# DSS_EDP0_V2A_CORE_VP_REGS_APB register map
Vendor: Texas Instruments
Registers are 32-bit, access per field, reset 0x0 unless marked. A register's access mark holds for its fields unless they carry their own. Offsets are as the file gives them; [hi:lo] are bit positions; {n}, {i} and the like mark numbered series.

## DSS_EDP0_V2A_CORE_VP_REGS_APB (part 3 of 3)
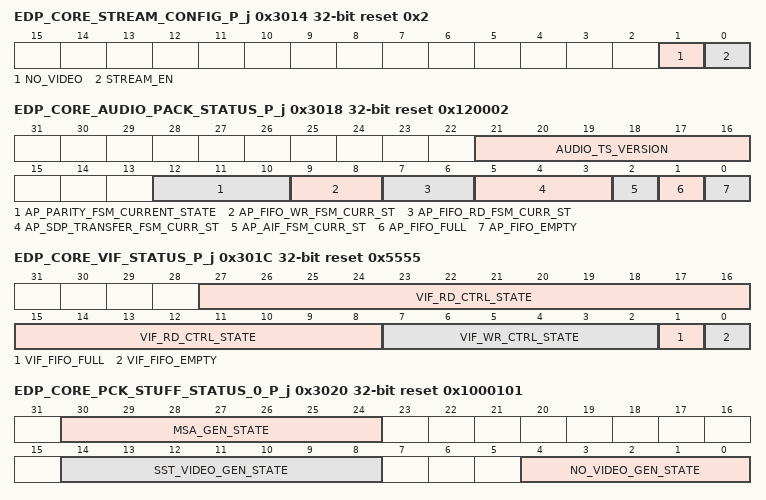
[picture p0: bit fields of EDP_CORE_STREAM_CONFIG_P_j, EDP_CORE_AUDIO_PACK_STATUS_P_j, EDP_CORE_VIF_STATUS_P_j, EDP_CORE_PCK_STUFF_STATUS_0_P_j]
0x3014 EDP_CORE_STREAM_CONFIG_P_j reset 0x2 — Stream configuration register. Used only in MST mode. Offset = 3014h + (j * 80h); where j = 0h to 3h
  [1] NO_VIDEO rw — Stream no video mode.
  [0] STREAM_EN rw — Stream enable.
0x3018 EDP_CORE_AUDIO_PACK_STATUS_P_j reset 0x120002 — Status signals for the audio pack. Offset = 3018h + (j * 80h); where j = 0h to 3h
  [21:16] AUDIO_TS_VERSION rw — Audio timestamp version.
  [12:10] AP_PARITY_FSM_CURRENT_STATE ro — Audio pack parity calc fsm state.
  [9:8] AP_FIFO_WR_FSM_CURR_ST ro — Audio pack FIFO write fsm state.
  [7:6] AP_FIFO_RD_FSM_CURR_ST ro — Audio pack FIFO read fsm state.
  [5:3] AP_SDP_TRANSFER_FSM_CURR_ST ro — Audio pack sdp transfer fsm state.
  [2] AP_AIF_FSM_CURR_ST ro — Audio pack aif fsm state.
  [1] AP_FIFO_FULL ro — Audio Pack Sync FIFO full flag, active high.
  [0] AP_FIFO_EMPTY ro — Audio Pack Sync FIFO empty flag, active high.
0x301C EDP_CORE_VIF_STATUS_P_j ro reset 0x5555 — Status signals for the VIF module. Used only for debug purposes. Offset = 301Ch + (j * 80h); where j = 0h to 3h
  [27:8] VIF_RD_CTRL_STATE — VIF rd fsm current state.
  [7:2] VIF_WR_CTRL_STATE — VIF wr fsm current state.
  [1] VIF_FIFO_FULL — VIF ASync FIFO full flag, active high.
  [0] VIF_FIFO_EMPTY — VIF ASync FIFO empty flag, active high.
0x3020 EDP_CORE_PCK_STUFF_STATUS_0_P_j ro reset 0x1000101 — Status of the the video stuff module (0). Used only for debug purposes. Offset = 3020h + (j * 80h); where j = 0h to 3h
  [30:24] MSA_GEN_STATE — Secondary Data generator FSM status.
  [14:8] SST_VIDEO_GEN_STATE — SST video generator FSM status.
  [4:0] NO_VIDEO_GEN_STATE — No video generator FSM status.
0x3024 EDP_CORE_PCK_STUFF_STATUS_1_P_j ro reset 0x1 — Status of the the video stuff module (1). Used only for debug purposes. Offset = 3024h + (j * 80h); where j = 0h to 3h
  [5:0] SST_SS_GEN_STATE — MSA generator FSM status.
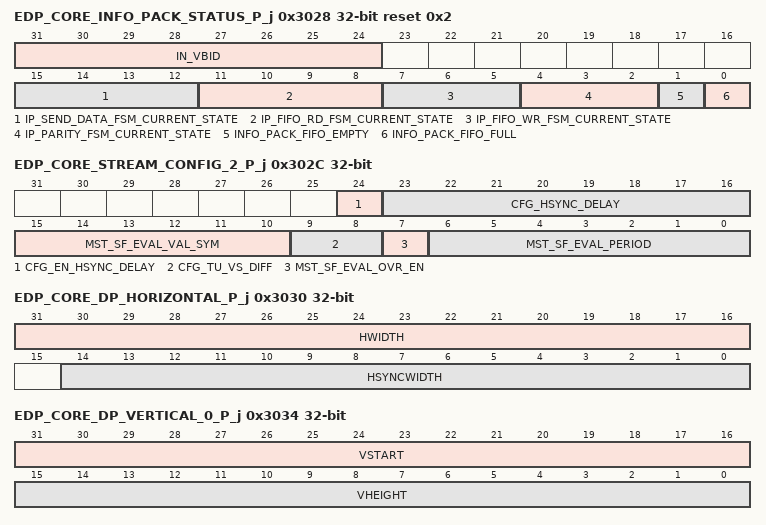
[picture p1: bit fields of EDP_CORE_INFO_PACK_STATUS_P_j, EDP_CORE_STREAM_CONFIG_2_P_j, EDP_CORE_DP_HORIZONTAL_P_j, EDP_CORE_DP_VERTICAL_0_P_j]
0x3028 EDP_CORE_INFO_PACK_STATUS_P_j ro reset 0x2 — Status signals for the info pack module, as well as final VB-ID value. Used only for debug purposes. Offset = 3028h + (j * 80h); where j = 0h to 3h
  [31:24] IN_VBID — Value of the sent VB-ID [vb_id_final].
  [15:12] IP_SEND_DATA_FSM_CURRENT_STATE — State of the send_data FSM.
  [11:8] IP_FIFO_RD_FSM_CURRENT_STATE — State of the fifo_rd FSM.
  [7:5] IP_FIFO_WR_FSM_CURRENT_STATE — State of the fifo_wr FSM.
  [4:2] IP_PARITY_FSM_CURRENT_STATE — State of the parity FSM.
  [1] INFO_PACK_FIFO_EMPTY — Info_pack fifo empty flag, active high.
  [0] INFO_PACK_FIFO_FULL — Info_pack fifo full flag, active high.
0x302C EDP_CORE_STREAM_CONFIG_2_P_j — Additional video stream configuration. Used for debug purposes or for non-standard video formats. Offset = 302Ch + (j * 80h); where j = 0h to 3h
  [24] CFG_EN_HSYNC_DELAY rw — Unused.
  [23:16] CFG_HSYNC_DELAY rw — Unused.
  [15:10] MST_SF_EVAL_VAL_SYM rw — Number of valid symbols to output during stream fill evaluation period.
  [9:8] CFG_TU_VS_DIFF rw — Unused.
  [7] MST_SF_EVAL_OVR_EN rw — Enable override of mst_sf_eval_period, mst_sf_eval_val_sym and cfg_tu_vs_diff when in MST mode.
  [6:0] MST_SF_EVAL_PERIOD rw — Stream fill evaluation period when in MST mode and mst_sf_eval_ovr_en bit is set.
0x3030 EDP_CORE_DP_HORIZONTAL_P_j — Video Horizontal parameters. This register must be programmed prior enabling video and must not be changed while video is being transmitted.In case of compressed stream transmission (DSC) and split panel mode values in this register must be divided by 2 since VIF interface operates at pixel clock divided by 2. This will ensure the same timing compared to uncompressed stream and. Offset = 3030h + (j * 80h); where j = 0h to 3h
  [31:16] HWIDTH rw — Horizontal Active Video Width.
  [14:0] HSYNCWIDTH rw — Horizontal Sync Width.
0x3034 EDP_CORE_DP_VERTICAL_0_P_j rw — Video Vertical parameters. This register must be programmed prior enabling video and must not be changed while video is being transmitted. Offset = 3034h + (j * 80h); where j = 0h to 3h
  [31:16] VSTART — Vertical Active Start [VSTART].
  [15:0] VHEIGHT — Vertical Active High [VACTIVE].
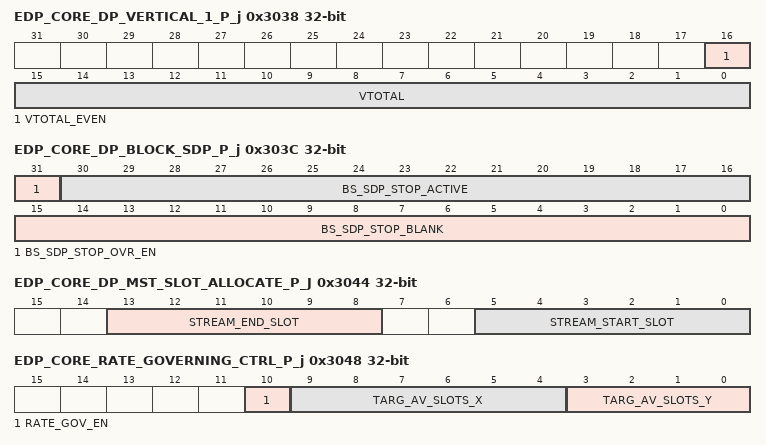
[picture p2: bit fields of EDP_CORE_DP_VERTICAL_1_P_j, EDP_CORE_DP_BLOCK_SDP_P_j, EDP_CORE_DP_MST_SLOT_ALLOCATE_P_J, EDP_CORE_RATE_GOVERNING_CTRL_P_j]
0x3038 EDP_CORE_DP_VERTICAL_1_P_j — Video Vertical parameters. This register must be programmed prior enabling video and must not be changed while video is being transmitted. Offset = 3038h + (j * 80h); where j = 0h to 3h
  [16] VTOTAL_EVEN rw — Indicate Vtotal is an even number as described in MISC1[0] in DisplayPort specification.
  [15:0] VTOTAL rw — Vertical Total Heigh [HTOTAL].
0x303C EDP_CORE_DP_BLOCK_SDP_P_j rw — SDP scheduling control register. Allows for tuning when SDP can be sent during blanking periods. This register must be programmed prior enabling video and must not be changed while video is being transmitted. Offset = 303Ch + (j * 80h); where j = 0h to 3h
  [31] BS_SDP_STOP_OVR_EN — Enable override settings.
  [30:16] BS_SDP_STOP_ACTIVE — Block SDP scheduling after specified cycles after BS during horizontal blank lines.
  [15:0] BS_SDP_STOP_BLANK — Block SDP scheduling after specified cycles after BS during vertical blank lines.
0x3044 EDP_CORE_DP_MST_SLOT_ALLOCATE_P_J — Stream slots allocation in MST mode. This register defines slots in the MTP assigned to a given stream. All slots between start and and are assigned to the stream. Assignement of noncontiguous slots to a single stream is not supported. Offset = 3044h + (j * 80h); where j = 0h to 3h
  [13:8] STREAM_END_SLOT rw, [5:0] STREAM_START_SLOT rw
0x3048 EDP_CORE_RATE_GOVERNING_CTRL_P_j — Control rate governing for stream in MST mode. Offset = 3048h + (j * 80h); where j = 0h to 3h
  [10] RATE_GOV_EN rw — Enable rate governing.
  [9:4] TARG_AV_SLOTS_X rw — Target average number of slots per MTP configuration
  [3:0] TARG_AV_SLOTS_Y rw — Target average number of slots per MTP configuration.
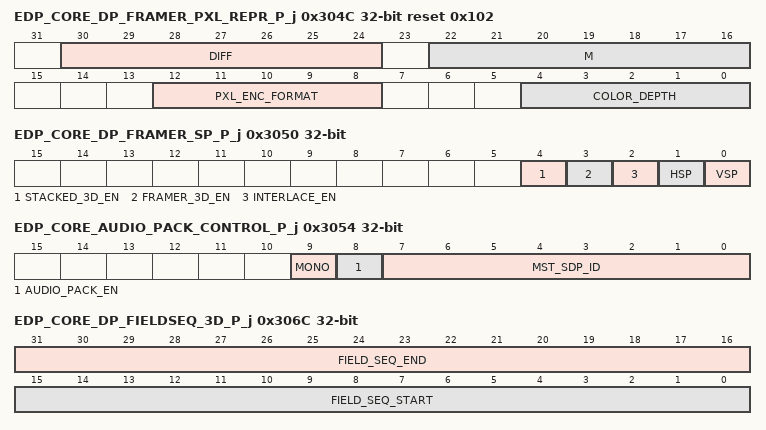
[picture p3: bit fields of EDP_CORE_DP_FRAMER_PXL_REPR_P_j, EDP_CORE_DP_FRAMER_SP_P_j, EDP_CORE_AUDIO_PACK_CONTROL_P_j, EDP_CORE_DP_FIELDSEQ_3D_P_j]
0x304C EDP_CORE_DP_FRAMER_PXL_REPR_P_j reset 0x102 — Video pixel format configuration. This register must be programmed prior enabling video and must not be changed while video is being transmitted. Offset = 304Ch + (j * 80h); where j = 0h to 3h
  [30:24] DIFF rw — Difference between Denominator and Numerator of the ratio that describes valid symbols distribution.
  [22:16] M rw — Numerator of the ratio that describes valid symbols distribution.
  [12:8] PXL_ENC_FORMAT rw — Pixel encoding format:
  [4:0] COLOR_DEPTH rw
0x3050 EDP_CORE_DP_FRAMER_SP_P_j — Synchronization signals polarity and 3D control. This register must be programmed prior enabling video and must not be changed while video is being transmitted. Offset = 3050h + (j * 80h); where j = 0h to 3h
  [4] STACKED_3D_EN rw — Unused.
  [3] FRAMER_3D_EN rw — 3D video enable, active high.
  [2] INTERLACE_EN rw — Interlaced video enable.
  [1] HSP rw — Video interface HSYNC polarity:
  [0] VSP rw — Video interface VSYNC polarity:
0x3054 EDP_CORE_AUDIO_PACK_CONTROL_P_j — Audio packet configuration. Offset = 3054h + (j * 80h); where j = 0h to 3h
  [9] MONO rw — In case of
  [8] AUDIO_PACK_EN rw — Enables the Audio_Pack module, active high
  [7:0] MST_SDP_ID rw — Secondary-Data Packet ID.
0x3064 EDP_CORE_LINE_THRESH_P_j reset 0x20 — Video FIFO latency threshold Offset = 3064h + (j * 80h); where j = 0h to 3h
  [5:0] CFG_ACTIVE_LINE_TRESH rw — Video Fifo Latency threshold.
0x3068 EDP_CORE_DP_VB_ID_P_J reset 0x9 — Vertical blanking ID Offset = 3068h + (j * 80h); where j = 0h to 3h
  [7:0] VB_ID rw — VB-ID as described in the DisplayPort specification.
0x306C EDP_CORE_DP_FIELDSEQ_3D_P_j rw — Supporting configuration to switch from top/bottom on the input to field sequential on the output Offset = 306Ch + (j * 80h); where j = 0h to 3h
  [31:16] FIELD_SEQ_END — Number of line in the frame where the Vblank part in the field sequential format ends
  [15:0] FIELD_SEQ_START — Number of line in the frame where the Vblank part in the field sequential format starts
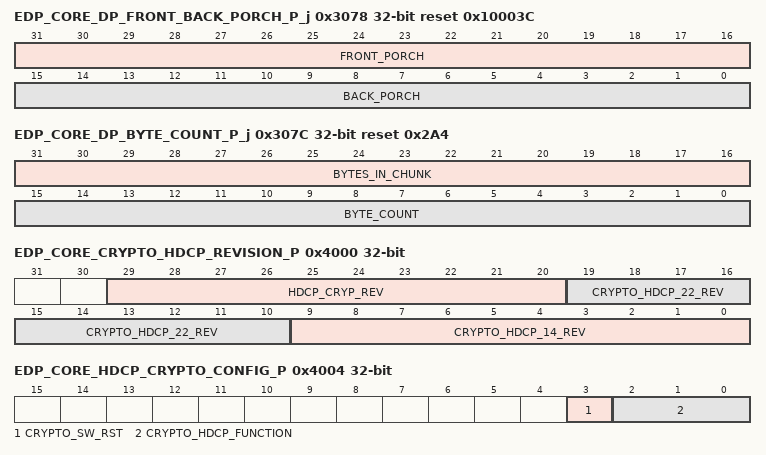
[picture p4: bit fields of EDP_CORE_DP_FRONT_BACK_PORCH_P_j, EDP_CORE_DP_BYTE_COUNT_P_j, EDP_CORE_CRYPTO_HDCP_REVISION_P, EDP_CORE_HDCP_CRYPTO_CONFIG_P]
0x3078 EDP_CORE_DP_FRONT_BACK_PORCH_P_j rw reset 0x10003C — Front and Back Porch configuration register.In case of compressed stream transmission (DSC) and split panel mode values in this register must be divided by 2 since VIF interface operates at pixel clock divided by 2. This will ensure the same timing compared to uncompressed stream and. Offset = 3078h + (j * 80h); where j = 0h to 3h
  [31:16] FRONT_PORCH — Value of the front porch
  [15:0] BACK_PORCH — Value of the back porch
0x307C EDP_CORE_DP_BYTE_COUNT_P_j rw reset 0x2A4 — Number of bytes per lane/chunk parameters Offset = 307Ch + (j * 80h); where j = 0h to 3h
  [31:16] BYTES_IN_CHUNK — Number of bytes in chunk per lane, including additional EOC symbol.
  [15:0] BYTE_COUNT — Total number of bytes in a line in case of non-DSC video.
0x4000 EDP_CORE_CRYPTO_HDCP_REVISION_P ro — Contains the revision of the internal HDCP 1.4 and 2.2 module.
  [29:20] HDCP_CRYP_REV — Revision of the HDCP Crypto block.
  [19:10] CRYPTO_HDCP_22_REV — Revision of the HDCP Crypto 2.2 block.
  [9:0] CRYPTO_HDCP_14_REV — Revision of the HDCP Crypto 1.4 block.
0x4004 EDP_CORE_HDCP_CRYPTO_CONFIG_P — Contains global configuration information for the HDCP Crypto module.
  [3] CRYPTO_SW_RST rw — Software reset for the Crypto module.
  [2:0] CRYPTO_HDCP_FUNCTION rw — Enables a version of the Crypto function:
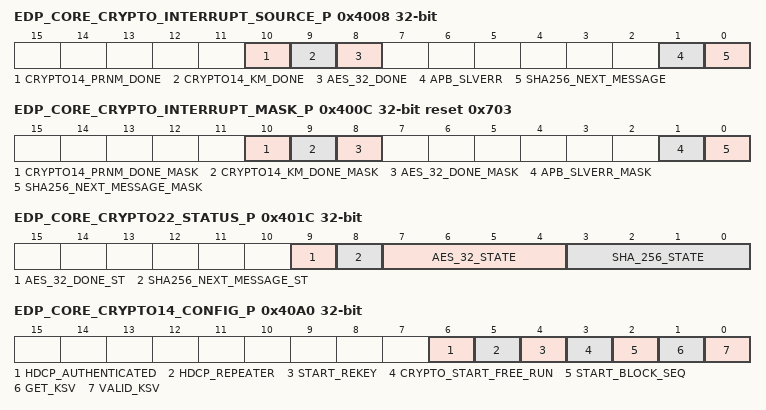
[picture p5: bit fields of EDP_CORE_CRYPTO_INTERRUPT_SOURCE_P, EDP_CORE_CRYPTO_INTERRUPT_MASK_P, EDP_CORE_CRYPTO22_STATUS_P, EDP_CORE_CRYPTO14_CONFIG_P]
0x4008 EDP_CORE_CRYPTO_INTERRUPT_SOURCE_P ro — Contains the status of the HDCP interrupt sources. These interrupts are used by firmware and not directly visible to the Host processor.
  [10] CRYPTO14_PRNM_DONE — LFSR and block output finished calculation.
  [9] CRYPTO14_KM_DONE — Done reading/calculating Km.
  [8] AES_32_DONE — Asserted when the rising edge of the AES-32 done output is detected.
  [1] APB_SLVERR — APB slave error.
  [0] SHA256_NEXT_MESSAGE — Asserted when the rising edge of the SHA256 done output is detected.
0x400C EDP_CORE_CRYPTO_INTERRUPT_MASK_P reset 0x703 — Contains the mask vector of the HDCP interrupt sources.
  [10] CRYPTO14_PRNM_DONE_MASK rw — Set to 1 to mask the crypto14_prnm_done interrupt.
  [9] CRYPTO14_KM_DONE_MASK rw — Set to 1 to mask the crypto14_km_done interrupt.
  [8] AES_32_DONE_MASK rw — Set to 1 to mask the AES32_done interrupt.
  [1] APB_SLVERR_MASK rw — Set to 1 for the apb_slverr interrupt.
  [0] SHA256_NEXT_MESSAGE_MASK rw — Set to 1 to mask the SHA256_done interrupt.
0x4018 EDP_CORE_CRYPTO22_CONFIG_P — Contains global configuration information for the HDCP 2.2 Crypto module
  [0] SHA_256_START rw — Set to 1 for Sha-256 start.
0x401C EDP_CORE_CRYPTO22_STATUS_P ro — Crypto 2.2 global status register.
  [9] AES_32_DONE_ST — Asserted when the rising edge of the AES-32 done output is detected.
  [8] SHA256_NEXT_MESSAGE_ST — Asserted when the SHA-256 module is ready to receive the next message.
  [7:4] AES_32_STATE — AES-32 current state.
  [3:0] SHA_256_STATE — SHA-256 current state.
0x403C EDP_CORE_SHA_256_DATA_IN_P rw — Holds 32-bit input data word of the SHA-256 module.
  [31:0] SHA_256_DATA_IN — Holds the 32-bit input data word of the SHA-256 module.
0x4050 EDP_CORE_SHA_256_DATA_OUT_0_P ro — Result of operation SHA-256 - 1' dw
  [31:0] SHA_256_DATA_OUT_0 — Holds the least significant 32-bits word of the 256-bits output data word of the SHA-256 module.
0x4054 EDP_CORE_SHA_256_DATA_OUT_1_P ro — Result of operation SHA-256 - 2' dw
  [31:0] SHA_256_DATA_OUT_1 — Holds the next significant 32-bits word of the 256-bits output data word of the SHA-256 module.
0x4058 EDP_CORE_SHA_256_DATA_OUT_2_P ro — Result of operation SHA-256 - 3' dw
  [31:0] SHA_256_DATA_OUT_2 — Holds the next significant 32-bits word of the 256-bits output data word of the SHA-256 module
{0x4050+4i} EDP_CORE_SHA_256_DATA_OUT_{i}_P ro (i=3..6) — Result of operation SHA-256 - {i+1}' dw
  [31:0] SHA_256_DATA_OUT_{i} — Holds the next significant 32-bits word of the 256-bits output data word of the SHA-256 module.
0x406C EDP_CORE_SHA_256_DATA_OUT_7_P ro — Result of operation SHA-256 - 8' dw
  [31:0] SHA_256_DATA_OUT_7 — Holds the most significant 32-bits word of the 256-bits output data word of the SHA-256 module.
0x4070 EDP_CORE_AES_32_KEY_0_P rw — Input key word of the AES-32 module - 1' dw
  [31:0] AES_32_KEY_0 — Holds the least significant 32-bits word of the 128-bits input key word of the AES-32 module.
0x4074 EDP_CORE_AES_32_KEY_1_P rw — Input key word of the AES-32 module - 2' dw
  [31:0] AES_32_KEY_1 — Holds the next significant 32-bits word of the 128-bits input key word of the AES-32 module.
0x4078 EDP_CORE_AES_32_KEY_2_P rw — Input key word of the AES-32 module - 3' dw
  [31:0] AES_32_KEY_2 — Holds the next significant 32-bits word of the 128-bits input key word of the AES-32 module.
0x407C EDP_CORE_AES_32_KEY_3_P rw — Input key word of the AES-32 module - 4' dw
  [31:0] AES_32_KEY_3 — Holds the most significant 32-bits word of the 128-bits input key word of the AES-32 module.
0x4080 EDP_CORE_AES_32_DATA_IN_P rw — Input data word to the AES-32 module
  [31:0] AES_32_DATA_IN — Holds the input data word to the AES-32 module.
0x4084 EDP_CORE_AES_32_DATA_OUT_0_P ro — AES-32 module - 128-bits output data word - 1' dw
  [31:0] AES_32_DATA_OUT_0 — Holds the least significant 32-bits word of the 128-bits output data word of the AES-32 module.
0x4088 EDP_CORE_AES_32_DATA_OUT_1_P ro — AES-32 module - 128-bits output data word - 2' dw
  [31:0] AES_32_DATA_OUT_1 — Holds the next significant 32-bits word of the 128-bits output data word of the AES-32 module.
0x408C EDP_CORE_AES_32_DATA_OUT_2_P ro — AES-32 module - 128-bits output data word - 3' dw
  [31:0] AES_32_DATA_OUT_2 — Holds the next significant 32-bits word of the 128-bits output data word of the AES-32 module.
0x4090 EDP_CORE_AES_32_DATA_OUT_3_P ro — AES-32 module - 128-bits output data word - 4' dw
  [31:0] AES_32_DATA_OUT_3 — Holds the most significant 32-bits word of the 128-bits output data word of the AES-32 module.
0x40A0 EDP_CORE_CRYPTO14_CONFIG_P — Contains global configuration information for the HDCP 1.4 Crypto module
  [6] HDCP_AUTHENTICATED rw — Authenticated finished.
  [5] HDCP_REPEATER rw — Repeater bit :
  [4] START_REKEY rw — Crypto 1.4 command to start hdcpRekeyCipher
  [3] CRYPTO_START_FREE_RUN rw — Crypto 1.4 command to start free running enable for operation hdcpRngCipher
  [2] START_BLOCK_SEQ rw — Crypto 1.4 command to start LFSR calculation
  [1] GET_KSV rw — Read it's own KSV enable bit.'0' reading not allowed'1' start reading.
  [0] VALID_KSV rw — Enable for Km calculation.
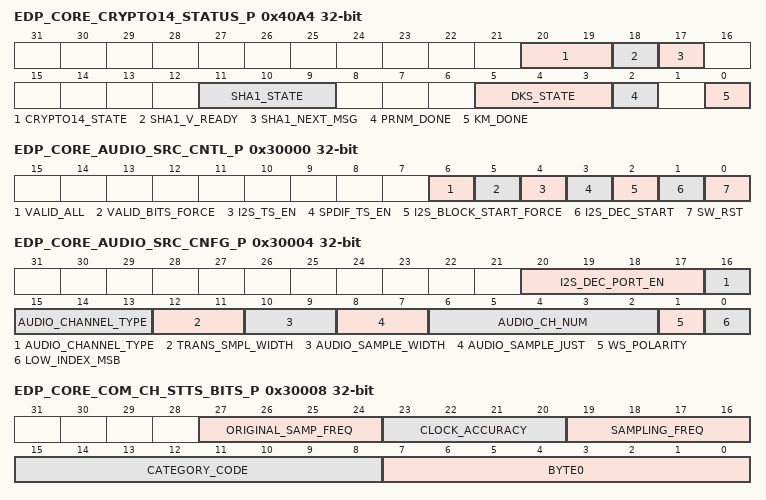
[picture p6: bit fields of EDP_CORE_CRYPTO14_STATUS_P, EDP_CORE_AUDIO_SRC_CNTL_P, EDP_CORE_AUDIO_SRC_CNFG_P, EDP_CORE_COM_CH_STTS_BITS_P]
0x40A4 EDP_CORE_CRYPTO14_STATUS_P ro — Contains global status information for the HDCP 1.4 Crypto module
  [20:19] CRYPTO14_STATE — Crypto operation SM state: Possible values:
  [18] SHA1_V_READY — Indication that V value from SHA-1 CRYPTO14_SHA1_V_VALUE_4 is ready.
  [17] SHA1_NEXT_MSG — Request for the next message block.
  [11:9] SHA1_STATE — Current state for Crypto 1.4 SHA-1 FSM.
  [5:3] DKS_STATE — Crypto 1.4 DKS current state.
  [2] PRNM_DONE — LFSR and block output finished calculation.
  [0] KM_DONE — Done reading/calculating Km.
0x40A8 EDP_CORE_CRYPTO14_PRNM_OUT_P ro — Contains 24-bit pseudo random data
  [23:0] PRNM_OUT
0x40AC EDP_CORE_CRYPTO14_KM_0_P ro — Contains the first word of the Km value
  [31:0] CRYPTO14_KM_0 — Holds the first word of the Km value.
0x40B0 EDP_CORE_CRYPTO14_KM_1_P ro — Contains the most significant 3 bytes of the Km value
  [23:0] CRYPTO14_KM_1 — Holds the most significant 3 bytes of the Km value.
0x40B4 EDP_CORE_CRYPTO14_AN_0_P rw — First word of An value generated by hdcpRngCipher operation.
  [31:0] CRYPTO14_AN_0 — Holds the first 4 bytes of the An value.
0x40B8 EDP_CORE_CRYPTO14_AN_1_P rw — Second word of An value generated by hdcpRngCipher operation
  [31:0] CRYPTO14_AN_1 — Holds the most significant 4 bytes of the An value.
0x40BC EDP_CORE_CRYPTO14_YOUR_KSV_0_P rw — First 32 bits of the KSV from the other HDCP device
  [31:0] CRYPTO14_YOUR_KSV_0 — Holds the first 32 bits of the KSV from the other HDCP device.
0x40C0 EDP_CORE_CRYPTO14_YOUR_KSV_1_P — Last byte of the KSV from other HDCP device
  [7:0] CRYPTO14_YOUR_KSV_1 rw — Holds the last byte of the KSV from other HDCP device
0x40C4 EDP_CORE_CRYPTO14_MI_0_P ro — Mi value - 1' dw
  [31:0] CRYPTO14_MI_0 — Mi value first 32 bits
0x40C8 EDP_CORE_CRYPTO14_MI_1_P ro — Mi value - 2' dw
  [31:0] CRYPTO14_MI_1 — Mi value second 32 bits
0x40CC EDP_CORE_CRYPTO14_TI_0_P ro — Ti value
  [15:0] CRYPTO14_TI_0
0x40D0 EDP_CORE_CRYPTO14_KI_0_P ro — First 32 bits of the Ki frame key from this HDCP device
  [31:0] CRYPTO14_KI_0 — Holds the first 32 bits of the Ki frame key from this HDCP device.
0x40D4 EDP_CORE_CRYPTO14_KI_1_P ro — Last 3 bytes of the Ki frame key from this HDCP device.
  [23:0] CRYPTO14_KI_1 — Holds the last 3 bytes of the Ki frame key from this HDCP device.
0x40D8 EDP_CORE_CRYPTO14_BLOCKS_NUM_P rw — This register defines number of iterations for SHA-1 calculations
  [31:0] BLOCKS_NUM — Number of iterations for SHA-1 calculation.
0x40DC EDP_CORE_CRYPTO14_KEY_MEM_DATA_0_P rw — Key memory control register. Writing data to this register transfers data to the key RAM. This is input for DKS block. First 32 bits
  [31:0] KEY_MEM_DATA_0 — Output data from keys RAM.
0x40E0 EDP_CORE_CRYPTO14_KEY_MEM_DATA_1_P — Key memory control register. Writing data to this register transfers data to the key RAM. When data is written to this register, pulse key_mem_vld shall be also generated to the core_clk clock domain, as indication of new key_mem_data. This is input for DKS block. Last 3 bytes
  [23:0] KEY_MEM_DATA_1 rw — Output data from keys RAM.
0x40E4 EDP_CORE_CRYPTO14_SHA1_MSG_DATA_P rw — SHA1 message control register. 32-bit word for SHA-1 message. Input for SHA-1 block. Writing data to this register transfers data to the SHA-1 block. Write to this register shall be repeated 16 times.
  [31:0] SHA1_MSG_DATA — 32-bit word for SHA-1 message.
0x40E8 EDP_CORE_CRYPTO14_SHA1_V_VALUE_0_P ro reset 0x67452301 — SHA1 message status register. First 32-bit word for SHA-1 calculation. Output from SHA-1 block
  [31:0] V_VALUE_0 — First 32-bit word for SHA-1 calculation value.
0x40EC EDP_CORE_CRYPTO14_SHA1_V_VALUE_1_P ro reset 0xEFCDAB89 — SHA1 message status register. Second 32-bit word for SHA-1 calculation. Output from SHA-1 block
  [31:0] V_VALUE_1 — Second 32-bit word for SHA-1 calculation value.
0x40F0 EDP_CORE_CRYPTO14_SHA1_V_VALUE_2_P ro reset 0x98BADCFE — SHA1 message status register. Third 32-bit word for SHA-1 calculation. Output from SHA-1 block
  [31:0] V_VALUE_2 — Third 32-bit word for SHA-1 calculation value.
0x40F4 EDP_CORE_CRYPTO14_SHA1_V_VALUE_3_P ro reset 0x10325476 — SHA1 message status register. Third 32-bit word for SHA-1 calculation. Output from SHA-1 block
  [31:0] V_VALUE_3 — 4th 32-bit word for SHA-1 calculation value.
0x40F8 EDP_CORE_CRYPTO14_SHA1_V_VALUE_4_P ro reset 0xC3D2E1F0 — SHA1 message status register. 5th 32-bit word for SHA-1 calculation. Output from SHA-1 block
  [31:0] V_VALUE_4 — 5th 32-bit word for SHA-1 calculation value.
0x10000 EDP_CORE_IRAM_REG_P_y rw — Xtensa Instruction RAM address space. Accessed only during boot mode to load firmware. Offset = 00010000h + (y * 4h); where y = 0h to 3FFFh
  [31:0] IRAM_DATA
0x20000 EDP_CORE_DRAM_REG_P_y rw — Xtensa Data RAM address space. Accessed only during boot mode to load firmware. Offset = 00020000h + (y * 4h); where y = 0h to 3FFFh
  [31:0] DRAM_DATA
0x30000 EDP_CORE_AUDIO_SRC_CNTL_P — Audio source control
  [6] VALID_ALL rw — valid bit for all samples
  [5] VALID_BITS_FORCE rw — Force valid bits of the channels
  [4] I2S_TS_EN rw — Enable I2S Time Stamp when decoders are disabled
  [3] SPDIF_TS_EN rw — Enable SPDIF Time Stamp when decoders are disabled
  [2] I2S_BLOCK_START_FORCE rw — Force a Block Start in the audio stream
  [1] I2S_DEC_START rw — When high Source Decoder starts.
  [0] SW_RST rw — Software reset.
0x30004 EDP_CORE_AUDIO_SRC_CNFG_P — Audio source configuration
  [20:17] I2S_DEC_PORT_EN rw — Enables the I2S Decoder ports.
  [16:13] AUDIO_CHANNEL_TYPE rw — Set the transmission type.
  [12:11] TRANS_SMPL_WIDTH rw — Decoder Word Select width:
  [10:9] AUDIO_SAMPLE_WIDTH rw — Decoder sample width:
  [8:7] AUDIO_SAMPLE_JUST rw — Data justification setting:
  [6:2] AUDIO_CH_NUM rw — Number of channels to decode
  [1] WS_POLARITY rw — Word Select Polarity.
  [0] LOW_INDEX_MSB rw — When low MSB is transmitted first.
0x30008 EDP_CORE_COM_CH_STTS_BITS_P — Common channels configuration
  [27:24] ORIGINAL_SAMP_FREQ rw — Original Sampling Freq.
  [23:20] CLOCK_ACCURACY rw — Clock Accuracy of transmitted channel.
  [19:16] SAMPLING_FREQ rw — Sampling Frequency of transmitted channel.
  [15:8] CATEGORY_CODE rw — Category Code of transmitted channel.
  [7:0] BYTE0 rw — Byte 0 of transmitted channel.
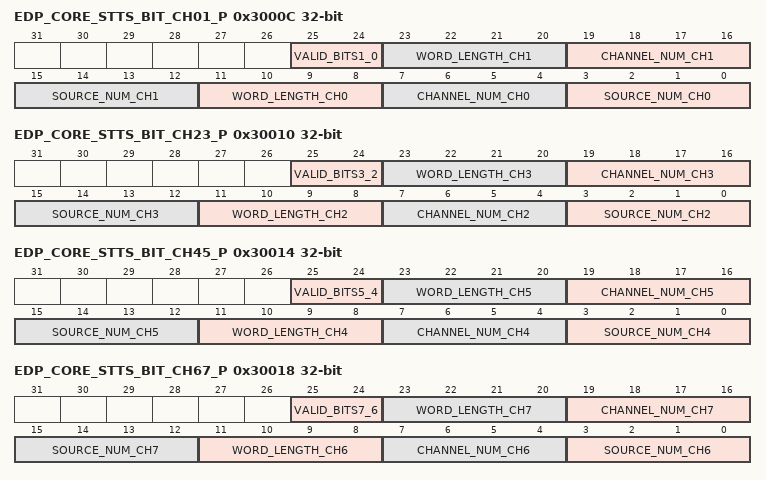
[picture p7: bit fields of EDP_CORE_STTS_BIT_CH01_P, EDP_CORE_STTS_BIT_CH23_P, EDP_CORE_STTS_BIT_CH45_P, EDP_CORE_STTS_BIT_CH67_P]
0x3000C EDP_CORE_STTS_BIT_CH01_P — Channels 0,1 configuration
  [25:24] VALID_BITS1_0 rw — Valid Bits for channel 1 and 0 if force is enabled
  [23:20] WORD_LENGTH_CH1 rw — Channel 1 word length.
  [19:16] CHANNEL_NUM_CH1 rw — Channel 1 channel number.
  [15:12] SOURCE_NUM_CH1 rw — Channel 1 Source number.
  [11:8] WORD_LENGTH_CH0 rw — Channel 0 word length.
  [7:4] CHANNEL_NUM_CH0 rw — Channel 0 channel number.
  [3:0] SOURCE_NUM_CH0 rw — Channel 0 Source number.
0x30010 EDP_CORE_STTS_BIT_CH23_P — Channels 2,3 configuration
  [25:24] VALID_BITS3_2 rw — Valid Bits for channel 3 and 2 if force is enabled
  [23:20] WORD_LENGTH_CH3 rw — Channel 3 word length.
  [19:16] CHANNEL_NUM_CH3 rw — Channel 3 channel number.
  [15:12] SOURCE_NUM_CH3 rw — Channel 3 Source number.
  [11:8] WORD_LENGTH_CH2 rw — Channel 2 word length.
  [7:4] CHANNEL_NUM_CH2 rw — Channel 2 channel number.
  [3:0] SOURCE_NUM_CH2 rw — Channel 2 Source number.
0x30014 EDP_CORE_STTS_BIT_CH45_P — Channels 4,5 configuration
  [25:24] VALID_BITS5_4 rw — Valid Bits for channel 5 and 4 if force is enabled
  [23:20] WORD_LENGTH_CH5 rw — Channel 5 word length.
  [19:16] CHANNEL_NUM_CH5 rw — Channel 5 channel number.
  [15:12] SOURCE_NUM_CH5 rw — Channel 5 Source number.
  [11:8] WORD_LENGTH_CH4 rw — Channel 4 word length.
  [7:4] CHANNEL_NUM_CH4 rw — Channel 4 channel number.
  [3:0] SOURCE_NUM_CH4 rw — Channel 4 Source number.
0x30018 EDP_CORE_STTS_BIT_CH67_P — Channels 6,7 configuration
  [25:24] VALID_BITS7_6 rw — Valid Bits for channel 7 and 6 if force is enabled
  [23:20] WORD_LENGTH_CH7 rw — Channel 7 word length.
  [19:16] CHANNEL_NUM_CH7 rw — Channel 7 channel number.
  [15:12] SOURCE_NUM_CH7 rw — Channel 7 Source number.
  [11:8] WORD_LENGTH_CH6 rw — Channel 6 word length.
  [7:4] CHANNEL_NUM_CH6 rw — Channel 6 channel number.
  [3:0] SOURCE_NUM_CH6 rw — Channel 6 Source number.
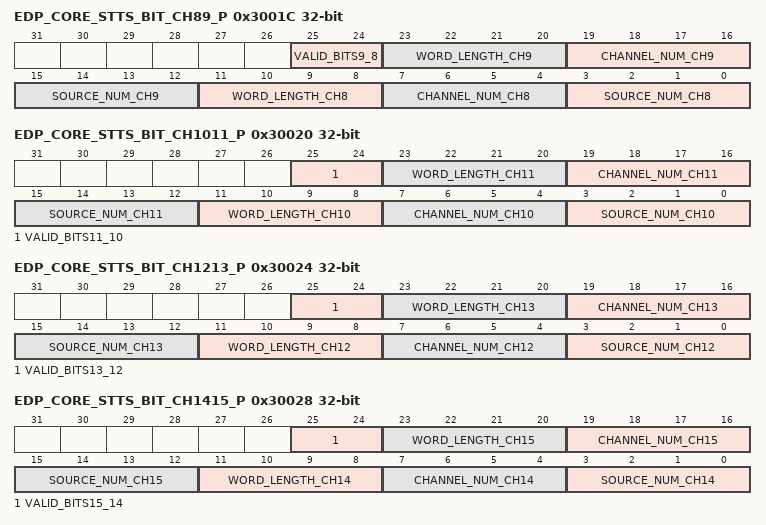
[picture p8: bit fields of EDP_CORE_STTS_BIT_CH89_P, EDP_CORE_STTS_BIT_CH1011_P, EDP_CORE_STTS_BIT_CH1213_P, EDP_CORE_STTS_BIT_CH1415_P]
0x3001C EDP_CORE_STTS_BIT_CH89_P — Channels 8,9 configuration
  [25:24] VALID_BITS9_8 rw — Valid Bits for channel 9 and 8 if force is enabled
  [23:20] WORD_LENGTH_CH9 rw — Channel 9 word length.
  [19:16] CHANNEL_NUM_CH9 rw — Channel 9 channel number.
  [15:12] SOURCE_NUM_CH9 rw — Channel 9 Source number.
  [11:8] WORD_LENGTH_CH8 rw — Channel 8 word length.
  [7:4] CHANNEL_NUM_CH8 rw — Channel 8 channel number.
  [3:0] SOURCE_NUM_CH8 rw — Channel 8 Source number.
0x30020 EDP_CORE_STTS_BIT_CH1011_P — Channels 10,11 configuration
  [25:24] VALID_BITS11_10 rw — Valid Bits for channel 11 and 10 if force is enabled
  [23:20] WORD_LENGTH_CH11 rw — Channel 11 word length.
  [19:16] CHANNEL_NUM_CH11 rw — Channel 11 channel number.
  [15:12] SOURCE_NUM_CH11 rw — Channel 11 Source number.
  [11:8] WORD_LENGTH_CH10 rw — Channel 10 word length.
  [7:4] CHANNEL_NUM_CH10 rw — Channel 10 channel number.
  [3:0] SOURCE_NUM_CH10 rw — Channel 10 Source number.
0x30024 EDP_CORE_STTS_BIT_CH1213_P — Channels 12,13 configuration
  [25:24] VALID_BITS13_12 rw — Valid Bits for channel 13 and 12 if force is enabled
  [23:20] WORD_LENGTH_CH13 rw — Channel 13 word length.
  [19:16] CHANNEL_NUM_CH13 rw — Channel 13 channel number.
  [15:12] SOURCE_NUM_CH13 rw — Channel 13 Source number.
  [11:8] WORD_LENGTH_CH12 rw — Channel 12 word length.
  [7:4] CHANNEL_NUM_CH12 rw — Channel 12 channel number.
  [3:0] SOURCE_NUM_CH12 rw — Channel 12 Source number.
0x30028 EDP_CORE_STTS_BIT_CH1415_P — Channels 14,15 configuration
  [25:24] VALID_BITS15_14 rw — Valid Bits for channel 15 and 14 if force is enabled
  [23:20] WORD_LENGTH_CH15 rw — Channel 15 word length.
  [19:16] CHANNEL_NUM_CH15 rw — Channel 15 channel number.
  [15:12] SOURCE_NUM_CH15 rw — Channel 15 Source number.
  [11:8] WORD_LENGTH_CH14 rw — Channel 14 word length.
  [7:4] CHANNEL_NUM_CH14 rw — Channel 14 channel number.
  [3:0] SOURCE_NUM_CH14 rw — Channel 14 Source number.
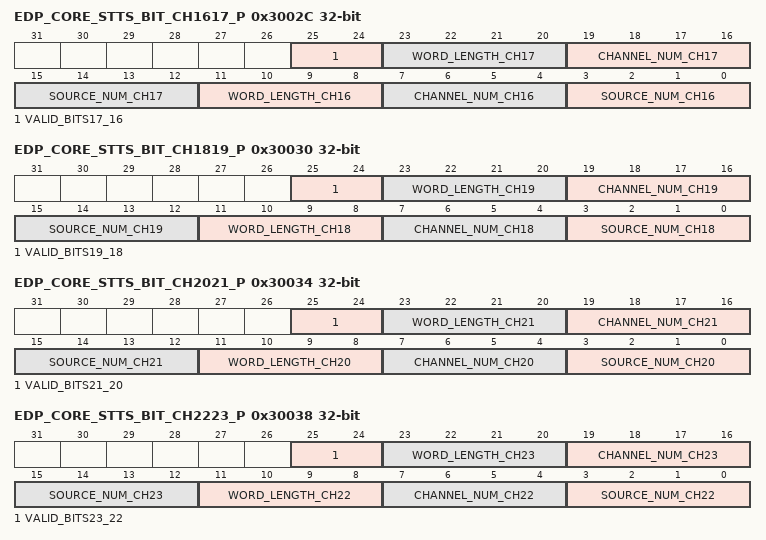
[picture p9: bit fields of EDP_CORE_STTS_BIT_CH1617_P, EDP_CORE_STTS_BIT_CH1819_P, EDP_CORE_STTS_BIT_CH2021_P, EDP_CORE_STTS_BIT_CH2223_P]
0x3002C EDP_CORE_STTS_BIT_CH1617_P — Channels 16,17 configuration
  [25:24] VALID_BITS17_16 rw — Valid Bits for channel 17 and 16 if force is enabled
  [23:20] WORD_LENGTH_CH17 rw — Channel 17 word length.
  [19:16] CHANNEL_NUM_CH17 rw — Channel 17 channel number.
  [15:12] SOURCE_NUM_CH17 rw — Channel 17 Source number.
  [11:8] WORD_LENGTH_CH16 rw — Channel 16 word length.
  [7:4] CHANNEL_NUM_CH16 rw — Channel 16 channel number.
  [3:0] SOURCE_NUM_CH16 rw — Channel 16 Source number.
0x30030 EDP_CORE_STTS_BIT_CH1819_P — Channels 18,19 configuration
  [25:24] VALID_BITS19_18 rw — Valid Bits for channel 19 and 18 if force is enabled
  [23:20] WORD_LENGTH_CH19 rw — Channel 19 word length.
  [19:16] CHANNEL_NUM_CH19 rw — Channel 19 channel number.
  [15:12] SOURCE_NUM_CH19 rw — Channel 19 Source number.
  [11:8] WORD_LENGTH_CH18 rw — Channel 18 word length.
  [7:4] CHANNEL_NUM_CH18 rw — Channel 18 channel number.
  [3:0] SOURCE_NUM_CH18 rw — Channel 18 Source number.
0x30034 EDP_CORE_STTS_BIT_CH2021_P — Channels 20,21 configuration
  [25:24] VALID_BITS21_20 rw — Valid Bits for channel 21 and 20 if force is enabled
  [23:20] WORD_LENGTH_CH21 rw — Channel 21 word length.
  [19:16] CHANNEL_NUM_CH21 rw — Channel 21 channel number.
  [15:12] SOURCE_NUM_CH21 rw — Channel 21 Source number.
  [11:8] WORD_LENGTH_CH20 rw — Channel 20 word length.
  [7:4] CHANNEL_NUM_CH20 rw — Channel 20 channel number.
  [3:0] SOURCE_NUM_CH20 rw — Channel 20 Source number.
0x30038 EDP_CORE_STTS_BIT_CH2223_P — Channels 22,23 configuration
  [25:24] VALID_BITS23_22 rw — Valid Bits for channel 23 and 22 if force is enabled
  [23:20] WORD_LENGTH_CH23 rw — Channel 23 word length.
  [19:16] CHANNEL_NUM_CH23 rw — Channel 23 channel number.
  [15:12] SOURCE_NUM_CH23 rw — Channel 23 Source number.
  [11:8] WORD_LENGTH_CH22 rw — Channel 22 word length.
  [7:4] CHANNEL_NUM_CH22 rw — Channel 22 channel number.
  [3:0] SOURCE_NUM_CH22 rw — Channel 22 Source number.
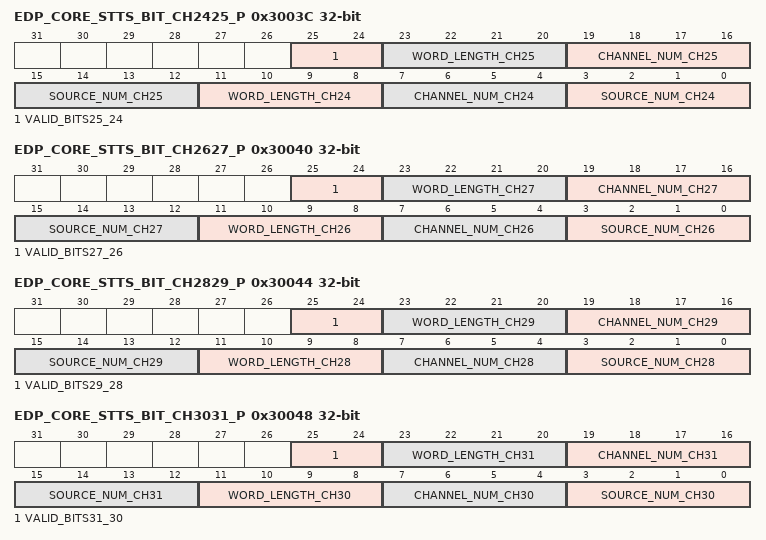
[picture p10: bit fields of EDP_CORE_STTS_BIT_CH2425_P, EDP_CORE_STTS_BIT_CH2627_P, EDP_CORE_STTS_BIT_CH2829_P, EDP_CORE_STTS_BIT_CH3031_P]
0x3003C EDP_CORE_STTS_BIT_CH2425_P — Channels 24,25 configuration
  [25:24] VALID_BITS25_24 rw — Valid Bits for channel 25 and 24 if force is enabled
  [23:20] WORD_LENGTH_CH25 rw — Channel 25 word length.
  [19:16] CHANNEL_NUM_CH25 rw — Channel 25 channel number.
  [15:12] SOURCE_NUM_CH25 rw — Channel 25 Source number.
  [11:8] WORD_LENGTH_CH24 rw — Channel 24 word length.
  [7:4] CHANNEL_NUM_CH24 rw — Channel 24 channel number.
  [3:0] SOURCE_NUM_CH24 rw — Channel 24 Source number.
0x30040 EDP_CORE_STTS_BIT_CH2627_P — Channels 26,27 configuration
  [25:24] VALID_BITS27_26 rw — Valid Bits for channel 27 and 26 if force is enabled
  [23:20] WORD_LENGTH_CH27 rw — Channel 27 word length.
  [19:16] CHANNEL_NUM_CH27 rw — Channel 27 channel number.
  [15:12] SOURCE_NUM_CH27 rw — Channel 27 Source number.
  [11:8] WORD_LENGTH_CH26 rw — Channel 26 word length.
  [7:4] CHANNEL_NUM_CH26 rw — Channel 26 channel number.
  [3:0] SOURCE_NUM_CH26 rw — Channel 26 Source number.
0x30044 EDP_CORE_STTS_BIT_CH2829_P — Channels 28,29 configuration
  [25:24] VALID_BITS29_28 rw — Valid Bits for channel 29 and 28 if force is enabled
  [23:20] WORD_LENGTH_CH29 rw — Channel 29 word length.
  [19:16] CHANNEL_NUM_CH29 rw — Channel 29 channel number.
  [15:12] SOURCE_NUM_CH29 rw — Channel 29 Source number.
  [11:8] WORD_LENGTH_CH28 rw — Channel 28 word length.
  [7:4] CHANNEL_NUM_CH28 rw — Channel 28 channel number.
  [3:0] SOURCE_NUM_CH28 rw — Channel 28 Source number.
0x30048 EDP_CORE_STTS_BIT_CH3031_P — Channels 30,31 configuration
  [25:24] VALID_BITS31_30 rw — Valid Bits for channel 31 and 30 if force is enabled
  [23:20] WORD_LENGTH_CH31 rw — Channel 31 word length.
  [19:16] CHANNEL_NUM_CH31 rw — Channel 31 channel number.
  [15:12] SOURCE_NUM_CH31 rw — Channel 31 Source number.
  [11:8] WORD_LENGTH_CH30 rw — Channel 30 word length.
  [7:4] CHANNEL_NUM_CH30 rw — Channel 30 channel number.
  [3:0] SOURCE_NUM_CH30 rw — Channel 30 Source number.
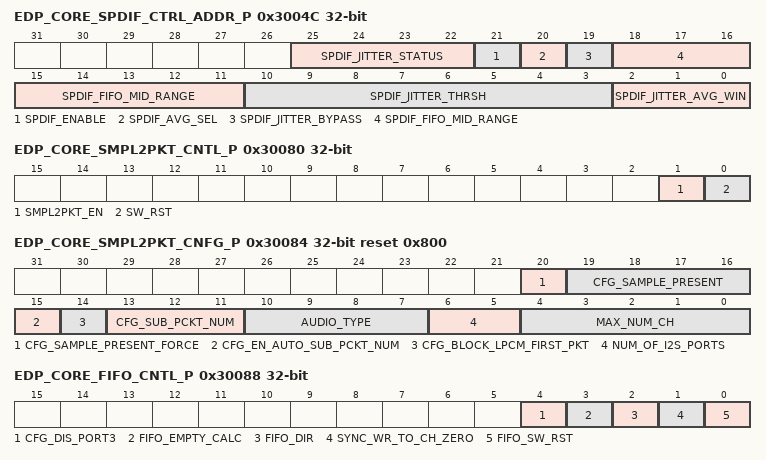
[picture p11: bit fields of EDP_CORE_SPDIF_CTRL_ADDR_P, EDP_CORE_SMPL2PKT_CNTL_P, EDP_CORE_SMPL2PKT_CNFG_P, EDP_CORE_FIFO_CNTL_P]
0x3004C EDP_CORE_SPDIF_CTRL_ADDR_P — SPDIF control
  [25:22] SPDIF_JITTER_STATUS ro
  [21] SPDIF_ENABLE rw
  [20] SPDIF_AVG_SEL rw — SPDIF average Select
  [19] SPDIF_JITTER_BYPASS rw
  [18:11] SPDIF_FIFO_MID_RANGE rw
  [10:3] SPDIF_JITTER_THRSH rw — SPDIF Jitter threshold
  [2:0] SPDIF_JITTER_AVG_WIN rw — Spdif Jitter AVG Window
0x30050 EDP_CORE_SPDIF_CH1_CS_3100_ADDR_P ro — SPDIF channel 1 status [31:00]
  [31:0] SPDIF_CH1_ST_STTS_BITS3100 — SPDIF Channel 1 Status bits[31:0]
0x30054 EDP_CORE_SPDIF_CH1_CS_6332_ADDR_P ro — SPDIF channel 1 status [63:32]
  [31:0] SPDIF_CH1_ST_STTS_BITS6332 — SPDIF Channel 1 Status bits[63:32]
0x30058 EDP_CORE_SPDIF_CH1_CS_9564_ADDR_P ro — SPDIF channel 1 status [95:64]
  [31:0] SPDIF_CH1_ST_STTS_BITS9564 — SPDIF Channel 1 Status bits[95:64]
0x3005C EDP_CORE_SPDIF_CH1_CS_12796_ADDR_P ro — SPDIF channel 1 status [127:96]
  [31:0] SPDIF_CH1_ST_STTS_BITS12796 — SPDIF Channel 1 Status bits[127:96]
0x30060 EDP_CORE_SPDIF_CH1_CS_159128_ADDR_P ro — SPDIF channel 1 status [159:128]
  [31:0] SPDIF_CH1_ST_STTS_BITS159128 — SPDIF Channel 1 Status bits[159:128]
0x30064 EDP_CORE_SPDIF_CH1_CS_191160_ADDR_P ro — SPDIF channel 1 status [191:160]
  [31:0] SPDIF_CH1_ST_STTS_BITS191160 — SPDIF Channel 1 Status bits[191:160]
0x30068 EDP_CORE_SPDIF_CH2_CS_3100_ADDR_P ro — SPDIF channel 2 status [31:00]
  [31:0] SPDIF_CH2_ST_STTS_BITS3100 — SPDIF Channel 2 Status bits[31:0]
0x3006C EDP_CORE_SPDIF_CH2_CS_6332_ADDR_P ro — SPDIF channel 2 status [63:32]
  [31:0] SPDIF_CH2_ST_STTS_BITS6332 — SPDIF Channel 2 Status bits[63:32]
0x30070 EDP_CORE_SPDIF_CH2_CS_9564_ADDR_P ro — SPDIF channel 2 status [95:64]
  [31:0] SPDIF_CH2_ST_STTS_BITS9564 — SPDIF Channel 2 Status bits[95:64]
0x30074 EDP_CORE_SPDIF_CH2_CS_12796_ADDR_P ro — SPDIF channel 2 status [127:96]
  [31:0] SPDIF_CH2_ST_STTS_BITS12796 — SPDIF Channel 2 Status bits[127:96]
0x30078 EDP_CORE_SPDIF_CH2_CS_159128_ADDR_P ro — SPDIF channel 2 status [159:128]
  [31:0] SPDIF_CH2_ST_STTS_BITS159128 — SPDIF Channel 2 Status bits[159:128]
0x3007C EDP_CORE_SPDIF_CH2_CS_191160_ADDR_P ro — SPDIF channel 2 status [191:160]
  [31:0] SPDIF_CH2_ST_STTS_BITS191160 — SPDIF Channel 2 Status bits[191:160]
0x30080 EDP_CORE_SMPL2PKT_CNTL_P — Sample 2 Packets Control Register
  [1] SMPL2PKT_EN rw — When high Sample to Packets Block starts.
  [0] SW_RST rw — Software reset.
0x30084 EDP_CORE_SMPL2PKT_CNFG_P reset 0x800 — Sample 2 Packets Config Register
  [20] CFG_SAMPLE_PRESENT_FORCE rw — Force sample present bits
  [19:16] CFG_SAMPLE_PRESENT rw — Sample present bits if force them is active
  [15] CFG_EN_AUTO_SUB_PCKT_NUM rw — Enable automatics sub packet number.
  [14] CFG_BLOCK_LPCM_FIRST_PKT rw
  [13:11] CFG_SUB_PCKT_NUM rw — Number of sub-packets in HDMI audio
  [10:7] AUDIO_TYPE rw — Audio Type setting.
  [6:5] NUM_OF_I2S_PORTS rw — Number ofactive I2S ports.
  [4:0] MAX_NUM_CH rw — Number of channels to decode.
0x30088 EDP_CORE_FIFO_CNTL_P — FIFO control register
  [4] CFG_DIS_PORT3 rw
  [3] FIFO_EMPTY_CALC rw
  [2] FIFO_DIR rw
  [1] SYNC_WR_TO_CH_ZERO rw — When high the last channel index synchronizes the write addresses [to the next channel group]
  [0] FIFO_SW_RST rw — Resets Fifo's write and read pointers.
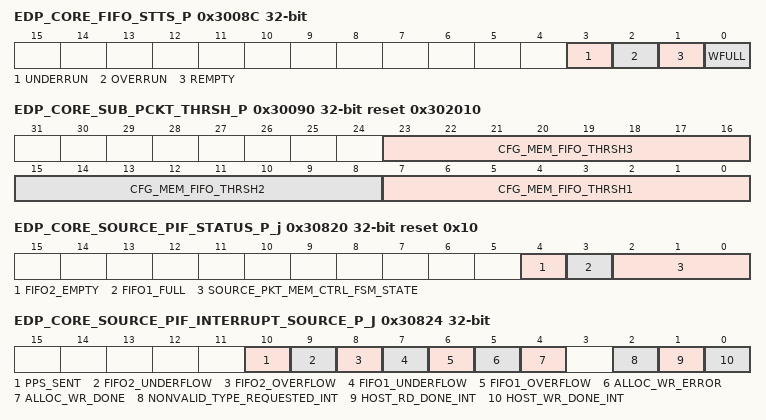
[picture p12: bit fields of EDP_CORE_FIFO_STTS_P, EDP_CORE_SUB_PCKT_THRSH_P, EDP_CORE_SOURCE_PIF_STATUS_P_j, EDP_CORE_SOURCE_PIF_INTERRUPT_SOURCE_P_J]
0x3008C EDP_CORE_FIFO_STTS_P ro — FIFO Status register
  [3] UNDERRUN — Indicates a FIFO underrun error has occured - FIFO read when it was empty.
  [2] OVERRUN — Indicates a FIFO overrun error has occured - FIFO written to when it was full.
  [1] REMPTY — Indicates FIFO Empty.
  [0] WFULL — Indicates FIFO Full.
0x30090 EDP_CORE_SUB_PCKT_THRSH_P reset 0x302010 — SUB Packet Threshold register
  [23:16] CFG_MEM_FIFO_THRSH3 rw — If number of samples in MEM FIFO is below Threshold
  [15:8] CFG_MEM_FIFO_THRSH2 rw — If number of samples in MEM FIFO is below Threshold
  [7:0] CFG_MEM_FIFO_THRSH1 rw — If number of samples in MEM FIFO is below Threshold
0x30800 EDP_CORE_SOURCE_PIF_WR_ADDR_P_j — 4 MSB of the packet memory address in which the data is written. Offset = 00030800h + (j * 40h); where j = 0h to 3h
  [3:0] WR_ADDR rw — 4 MSB of the packet memory address in which the data is written.
0x30804 EDP_CORE_SOURCE_PIF_WR_REQ_P_j — Write request bit for the host write transaction. Offset = 00030804h + (j * 40h); where j = 0h to 3h
  [0] HOST_WR rw — Write request bit for the host write transaction, active high.
0x30808 EDP_CORE_SOURCE_PIF_RD_ADDR_P_j — 4 MSB of the packet memory address from which the data is read. Offset = 00030808h + (j * 40h); where j = 0h to 3h
  [3:0] RD_ADDR rw — 4 MSB of the packet memory address from which the data is read.
0x3080C EDP_CORE_SOURCE_PIF_RD_REQ_P_j — Read request bit for the host read transaction. Offset = 0003080Ch + (j * 40h); where j = 0h to 3h
  [0] HOST_RD rw — Read request bit for the host read transaction, active high.
0x30810 EDP_CORE_SOURCE_PIF_DATA_WR_P_j rw — The 32 bits of the data to be written to the packet memory. Offset = 00030810h + (j * 40h); where j = 0h to 3h
  [31:0] DATA_WR — The 32 bits of the data to be written to the packet memory.
0x30814 EDP_CORE_SOURCE_PIF_DATA_RD_P_j ro — The 32 bits of the data to be read from the packet memory. Offset = 00030814h + (j * 40h); where j = 0h to 3h
  [31:0] FIFO2_DATA_OUT — The 32 bits of the data to be read from the packet memory.
0x30818 EDP_CORE_SOURCE_PIF_FIFO1_FLUSH_P_j — Fifo1 flush Offset = 00030818h + (j * 40h); where j = 0h to 3h
  [0] FIFO1_FLUSH rw — Fifo1 flush bit, active high.
0x3081C EDP_CORE_SOURCE_PIF_FIFO2_FLUSH_P_j — Fifo2 flush Offset = 0003081Ch + (j * 40h); where j = 0h to 3h
  [0] FIFO2_FLUSH rw — Fifo2 flush bit, active high.
0x30820 EDP_CORE_SOURCE_PIF_STATUS_P_j ro reset 0x10 — Status bits for the PIF module Offset = 00030820h + (j * 40h); where j = 0h to 3h
  [4] FIFO2_EMPTY — Fifo2 empty indication, when high indicates that FIFO2 is empty
  [3] FIFO1_FULL — Fifo1 full indication, when high indicates that FIFO1 is full
  [2:0] SOURCE_PKT_MEM_CTRL_FSM_STATE — State of the FSM that controls packet memory transactions.
0x30824 EDP_CORE_SOURCE_PIF_INTERRUPT_SOURCE_P_J ro — Interrupt sources of the PIF module, active high. Automatically cleared on read. If any of this interrupt is enabled and triggered bit apb_pif_intr_status in APB_INT_STATUS register is set. Offset = 00030824h + (j * 40h); where j = 0h to 3h
  [10] PPS_SENT — PPS sent to framer indication.
  [9] FIFO2_UNDERFLOW — Fifo2 underflow indication.
  [8] FIFO2_OVERFLOW — Fifo2 overflow indication.
  [7] FIFO1_UNDERFLOW — Fifo1 underflow indication.
  [6] FIFO1_OVERFLOW — Fifo1 overflow indication.
  [5] ALLOC_WR_ERROR — Error happened, invalid write to the allocation table.
  [4] ALLOC_WR_DONE — Successful write to the allocation table.
  [2] NONVALID_TYPE_REQUESTED_INT — Indication that nonvalid type of packet is requested by the packet interface.
  [1] HOST_RD_DONE_INT — Indication that the host read transaction finished.
  [0] HOST_WR_DONE_INT — Indication that the host write transaction finished.
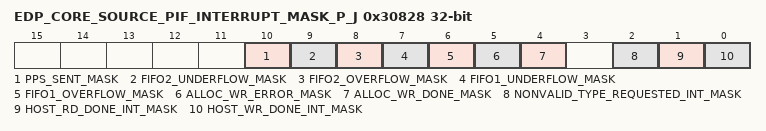
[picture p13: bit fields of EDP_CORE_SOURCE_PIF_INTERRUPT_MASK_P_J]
0x30828 EDP_CORE_SOURCE_PIF_INTERRUPT_MASK_P_J — Masks for the interrupt sources in the SOURCE_PIF_INTERRUPT_SOURCE register, when set high, these bits disable the corresponding interrupts Offset = 00030828h + (j * 40h); where j = 0h to 3h
  [10] PPS_SENT_MASK rw — Masks the pps_sent interrupt.
  [9] FIFO2_UNDERFLOW_MASK rw — Masks the fifo2_underflow interrupt.
  [8] FIFO2_OVERFLOW_MASK rw — Masks the fifo2_overflow interrupt.
  [7] FIFO1_UNDERFLOW_MASK rw — Masks the fifo1_underflow interrupt.
  [6] FIFO1_OVERFLOW_MASK rw — Masks the fifo1_overflow interrupt.
  [5] ALLOC_WR_ERROR_MASK rw — Masks the alloc_wr_error interrupt.
  [4] ALLOC_WR_DONE_MASK rw — Masks the alloc_wr_done interrupt.
  [2] NONVALID_TYPE_REQUESTED_INT_MASK rw — Masks the nonvalid_type_requested_int interrupt.
  [1] HOST_RD_DONE_INT_MASK rw — Masks the host_rd_done_int interrupt.
  [0] HOST_WR_DONE_INT_MASK rw — Masks the host_wr_done_int interrupt.
